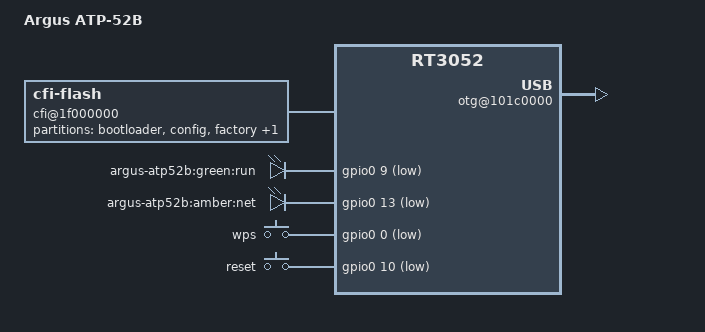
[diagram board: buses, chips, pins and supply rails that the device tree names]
/dts-v1/;

/include/ "rt3050.dtsi"

/ {
	compatible = "ARGUS_ATP52B", "ralink,rt3052-soc";
	model = "Argus ATP-52B";

	pinctrl {
		state_default: pinctrl0 {
			gpio {
				ralink,group = "i2c", "jtag", "rgmii", "mdio", "uartf";
				ralink,function = "gpio";
			};
		};
	};

	cfi@1f000000 {
		compatible = "cfi-flash";
		reg = <0x1f000000 0x800000>;

		bank-width = <2>;
		device-width = <2>;
		#address-cells = <1>;
		#size-cells = <1>;

		partition@0 {
			label = "bootloader";
			reg = <0x0 0x30000>;
			read-only;
		};

		partition@30000 {
			label = "config";
			reg = <0x30000 0x10000>;
		};

		factory: partition@40000 {
			label = "factory";
			reg = <0x40000 0x10000>;
		};

		partition@50000 {
			label = "firmware";
			reg = <0x50000 0x7a0000>;
		};
	};

	gpio-leds {
		compatible = "gpio-leds";
		run {
			label = "argus-atp52b:green:run";
			gpios = <&gpio0 9 1>;
		};
		net {
			label = "argus-atp52b:amber:net";
			gpios = <&gpio0 13 1>;
		};
	};

	gpio-keys-polled {
		compatible = "gpio-keys-polled";
		#address-cells = <1>;
		#size-cells = <0>;
		poll-interval = <20>;
		wps {
			label = "wps";
			gpios = <&gpio0 0 1>;
			linux,code = <0x211>;
		};
		reset {
			label = "reset";
			gpios = <&gpio0 10 1>;
			linux,code = <0x198>;
		};
	};

	esw@10110000 {
		ralink,portmap = <0x3e>;
	};

	otg@101c0000 {
		status = "okay";
	};
};
